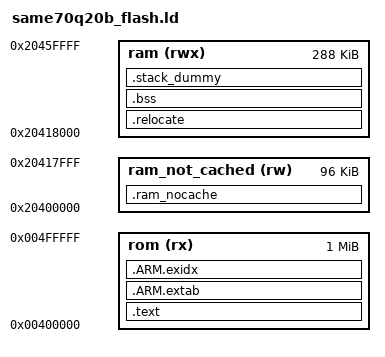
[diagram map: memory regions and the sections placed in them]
/**
 * \file
 *
 * Copyright (c) 2015 Atmel Corporation. All rights reserved.
 *
 * \asf_license_start
 *
 * \page License
 *
 * Redistribution and use in source and binary forms, with or without
 * modification, are permitted provided that the following conditions are met:
 *
 * 1. Redistributions of source code must retain the above copyright notice,
 *    this list of conditions and the following disclaimer.
 *
 * 2. Redistributions in binary form must reproduce the above copyright notice,
 *    this list of conditions and the following disclaimer in the documentation
 *    and/or other materials provided with the distribution.
 *
 * 3. The name of Atmel may not be used to endorse or promote products derived
 *    from this software without specific prior written permission.
 *
 * 4. This software may only be redistributed and used in connection with an
 *    Atmel microcontroller product.
 *
 * THIS SOFTWARE IS PROVIDED BY ATMEL "AS IS" AND ANY EXPRESS OR IMPLIED
 * WARRANTIES, INCLUDING, BUT NOT LIMITED TO, THE IMPLIED WARRANTIES OF
 * MERCHANTABILITY, FITNESS FOR A PARTICULAR PURPOSE AND NON-INFRINGEMENT ARE
 * EXPRESSLY AND SPECIFICALLY DISCLAIMED. IN NO EVENT SHALL ATMEL BE LIABLE FOR
 * ANY DIRECT, INDIRECT, INCIDENTAL, SPECIAL, EXEMPLARY, OR CONSEQUENTIAL
 * DAMAGES (INCLUDING, BUT NOT LIMITED TO, PROCUREMENT OF SUBSTITUTE GOODS
 * OR SERVICES; LOSS OF USE, DATA, OR PROFITS; OR BUSINESS INTERRUPTION)
 * HOWEVER CAUSED AND ON ANY THEORY OF LIABILITY, WHETHER IN CONTRACT,
 * STRICT LIABILITY, OR TORT (INCLUDING NEGLIGENCE OR OTHERWISE) ARISING IN
 * ANY WAY OUT OF THE USE OF THIS SOFTWARE, EVEN IF ADVISED OF THE
 * POSSIBILITY OF SUCH DAMAGE.
 *
 * \asf_license_stop
 *
 */

/*------------------------------------------------------------------------------
 *      Linker script for running in internal FLASH on the ATSAME70Q20
 *----------------------------------------------------------------------------*/

OUTPUT_FORMAT("elf32-littlearm", "elf32-littlearm", "elf32-littlearm")
OUTPUT_ARCH(arm)
SEARCH_DIR(.)

/* Memory Spaces Definitions */
/* We put the non-cached RAM at the start of RAM because the CAN buffers must be within the first 64kb. */
MEMORY
{
  rom (rx)  : ORIGIN = 0x00400000, LENGTH = 0x00100000
  ram_not_cached (rw) : ORIGIN = 0x20400000, LENGTH = 0x00018000		/* we currently allocate 96kb of non-cached RAM */
  ram (rwx) : ORIGIN = 0x20418000, LENGTH = 0x00048000					/* that leaves 288Kb of cached RAM */
}

/* Section Definitions */
SECTIONS
{
    .text :
    {
        . = ALIGN(4);
        _sfixed = .;
        KEEP(*(.vectors .vectors.*))
        *(.text .text.* .gnu.linkonce.t.*)
        *(.glue_7t) *(.glue_7)
        *(.rodata .rodata* .gnu.linkonce.r.*)

        /* Support C constructors, and C destructors in both user code
           and the C library. This also provides support for C++ code. */
        . = ALIGN(4);
        KEEP(*(.init))
        . = ALIGN(4);
        __preinit_array_start = .;
        KEEP (*(.preinit_array))
        __preinit_array_end = .;

        . = ALIGN(4);
        __init_array_start = .;
        KEEP (*(SORT(.init_array.*)))
        KEEP (*(.init_array))
        __init_array_end = .;

        . = ALIGN(0x4);
        KEEP (*crtbegin.o(.ctors))
        KEEP (*(EXCLUDE_FILE (*crtend.o) .ctors))
        KEEP (*(SORT(.ctors.*)))
        KEEP (*crtend.o(.ctors))

        . = ALIGN(4);
        KEEP(*(.fini))

        . = ALIGN(4);
        __fini_array_start = .;
        KEEP (*(.fini_array))
        KEEP (*(SORT(.fini_array.*)))
        __fini_array_end = .;

        KEEP (*crtbegin.o(.dtors))
        KEEP (*(EXCLUDE_FILE (*crtend.o) .dtors))
        KEEP (*(SORT(.dtors.*)))
        KEEP (*crtend.o(.dtors))

        . = ALIGN(4);
        _efixed = .;            /* End of text section */
    } > rom

	.ARM.extab :
    {
        *(.ARM.extab* .gnu.linkonce.armextab.*)
    } > rom

	/* .ARM.exidx is sorted, so has to go in its own output section.  */
    .ARM.exidx :
    {
		__exidx_start = .;
		*(.ARM.exidx* .gnu.linkonce.armexidx.*)
		__exidx_end = .;
    } > rom

    . = ALIGN(4);
    _etext = .;

 	.ram_nocache (NOLOAD) :
	{
        . = ALIGN(4);
        _szero_nocache = .;
		*(.CanMessage .CanMessage.*)
		*(.ram_nocache .ram_nocache.*)
        . = ALIGN(4);
        _ezero_nocache = .;
 	} > ram_not_cached
	
    .relocate : AT (_etext)
    {
        . = ALIGN(4);
        _srelocate = .;
        *(.ramfunc .ramfunc.*);
		. = ALIGN(4);
		_eramfunc = .;
        *(.data .data.*);
        . = ALIGN(4);
        _erelocate = .;
    } > ram

  	_firmware_crc = _etext + (_erelocate - _srelocate);		/* We append the CRC32 to the binary file. This is its offset in memory. */

   /* .bss section which is used for uninitialized data */
    .bss ALIGN(4) (NOLOAD) :
    {
        . = ALIGN(4);
        _sbss = . ;
        _szero = .;
        *(.bss .bss.*)
        *(COMMON)
        . = ALIGN(4);
        _ebss = . ;
        _ezero = .;
    } > ram

    . = ALIGN(4);
    _end = . ;

   /* .stack_dummy section doesn't contains any symbols. It is only
       used for linker to calculate size of stack sections, and assign
       values to stack symbols later */
    .stack_dummy :
    {
        *(.stack*)
    } > ram

    /* Set stack top to end of ram, and stack limit move down by
     * size of stack_dummy section */
    __StackTop = ORIGIN(ram) + LENGTH(ram);
    __StackLimit = __StackTop - SIZEOF(.stack_dummy);
    PROVIDE(_sstack = __StackLimit);
    PROVIDE(_estack = __StackTop);

	PROVIDE(_nocache_ram_start = ORIGIN(ram_not_cached));
	PROVIDE(_nocache_ram_end = ORIGIN(ram_not_cached) + LENGTH(ram_not_cached));
}

